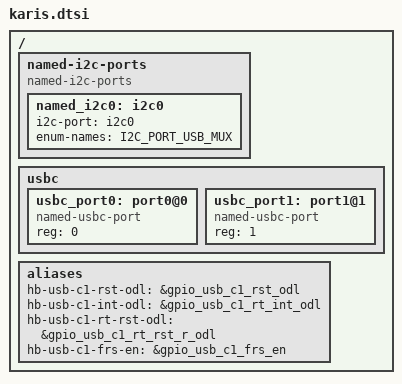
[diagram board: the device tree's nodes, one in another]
/* Copyright 2023 The ChromiumOS Authors
 * Use of this source code is governed by a BSD-style license that can be
 * found in the LICENSE file.
 */

#include "../native_posix.overlay"
#include "../../../../program/rex/karis/cbi.dtsi"

#include <dt-bindings/gpio_defines.h>

/ {
	/* Unused Stub */
	named-i2c-ports {
		compatible = "named-i2c-ports";

		named_i2c0: i2c0 {
			i2c-port = <&i2c0>;
			enum-names = "I2C_PORT_USB_MUX";
		};
	};

	usbc {
		#address-cells = <1>;
		#size-cells = <0>;

		usbc_port0: port0@0 {
			compatible = "named-usbc-port";
			reg = <0>;
		};
		usbc_port1: port1@1 {
			compatible = "named-usbc-port";
			reg = <1>;
		};
	};

	aliases {
		hb-usb-c1-rst-odl = &gpio_usb_c1_rst_odl;

		hb-usb-c1-int-odl = &gpio_usb_c1_rt_int_odl;

		hb-usb-c1-rt-rst-odl = &gpio_usb_c1_rt_rst_r_odl;

		hb-usb-c1-frs-en = &gpio_usb_c1_frs_en;
	};

};
